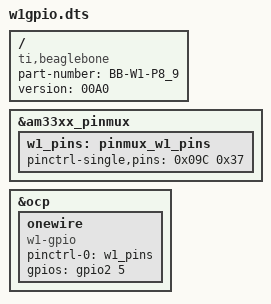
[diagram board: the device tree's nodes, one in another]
/dts-v1/;
/plugin/;

/ {
    compatible = "ti,beaglebone", "ti,beaglebone-black";
    part-number = "BB-W1-P8_9";
    version = "00A0";

    fragment@0 {
        target = <&am33xx_pinmux>;
        __overlay__ {
            w1_pins: pinmux_w1_pins {
                pinctrl-single,pins = <
                    0x09C 0x37
                >;
            };
        };
    };

    fragment@1 {
        target = <&ocp>;
        __overlay__ {
            onewire {
                compatible = "w1-gpio";
                pinctrl-names = "default";
                pinctrl-0 = <&w1_pins>;
                gpios = <&gpio2 5 0>;
                status = "okay";
            };
        };
    };
};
